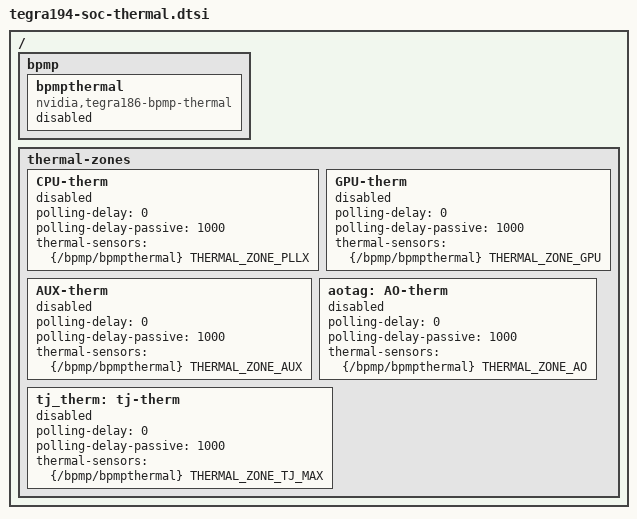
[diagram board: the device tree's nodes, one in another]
/*
 * Copyright (c) 2017-2018, NVIDIA CORPORATION.  All rights reserved.
 *
 * This program is free software; you can redistribute it and/or modify
 * it under the terms of the GNU General Public License as published by
 * the Free Software Foundation; version 2 of the License.
 *
 * This program is distributed in the hope that it will be useful, but WITHOUT
 * ANY WARRANTY; without even the implied warranty of MERCHANTABILITY or
 * FITNESS FOR A PARTICULAR PURPOSE.  See the GNU General Public License for
 * more details.
 *
 * You should have received a copy of the GNU General Public License along
 * with this program; if not, write to the Free Software Foundation, Inc.,
 * 51 Franklin Street, Fifth Floor, Boston, MA  02110-1301, USA.
 *
 */
#include <dt-bindings/thermal/tegra194-thermal.h>

/ {
	bpmp {
		bpmpthermal {
			compatible = "nvidia,tegra186-bpmp-thermal";
			#thermal-sensor-cells = <1>;
			status = "disabled";
		};
	};

	thermal-zones {
		CPU-therm {
			polling-delay = <0>;
			polling-delay-passive = <1000>;
			thermal-sensors = <&{/bpmp/bpmpthermal} THERMAL_ZONE_PLLX>;
			status = "disabled";
		};

		GPU-therm {
			polling-delay = <0>;
			polling-delay-passive = <1000>;
			thermal-sensors = <&{/bpmp/bpmpthermal} THERMAL_ZONE_GPU>;
			status = "disabled";
		};

		AUX-therm {
			polling-delay = <0>;
			polling-delay-passive = <1000>;
			thermal-sensors = <&{/bpmp/bpmpthermal} THERMAL_ZONE_AUX>;
			status = "disabled";
		};

		aotag: AO-therm {
			polling-delay = <0>;
			polling-delay-passive = <1000>;
			thermal-sensors = <&{/bpmp/bpmpthermal} THERMAL_ZONE_AO>;
			status = "disabled";
		};

		tj_therm: tj-therm {
			polling-delay = <0>;
			polling-delay-passive = <1000>;
			thermal-sensors = <&{/bpmp/bpmpthermal} THERMAL_ZONE_TJ_MAX>;
			status = "disabled";
		};
	};
};
